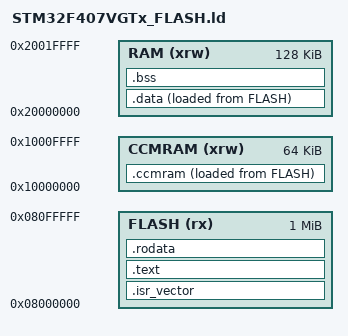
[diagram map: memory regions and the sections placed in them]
/**
 * @file     locate: linker/STM32F407VGTx_FLASH.ld
 * @author  Yigit Cakirdogan
 * @brief   Custom GNU LD Linker Script for STM32F407VGTx (1024KB Flash, 128KB SRAM, 64KB CCMRAM)
 */

ENTRY(Reset_Handler)

_estack = ORIGIN(RAM) + LENGTH(RAM);

_Min_Heap_Size  = 0x0000; /* Zero heap policy for deterministic bare-metal firmware */
_Min_Stack_Size = 0x1000; /* 4 KB Main Stack (MSP) */

MEMORY
{
  CCMRAM (xrw) : ORIGIN = 0x10000000, LENGTH = 64K
  RAM    (xrw) : ORIGIN = 0x20000000, LENGTH = 128K
  FLASH  (rx)  : ORIGIN = 0x08000000, LENGTH = 1024K
}

SECTIONS
{
  .isr_vector :
  {
    . = ALIGN(4);
    KEEP(*(.isr_vector))
    . = ALIGN(4);
  } >FLASH

  .text :
  {
    . = ALIGN(4);
    *(.text)
    *(.text*)
    *(.glue_7)
    *(.glue_7t)
    KEEP (*(.init))
    KEEP (*(.fini))
    . = ALIGN(4);
    _etext = .;
  } >FLASH

  .rodata :
  {
    . = ALIGN(4);
    *(.rodata)
    *(.rodata*)
    . = ALIGN(4);
  } >FLASH

  _sidata = LOADADDR(.data);

  .data :
  {
    . = ALIGN(4);
    _sdata = .;
    *(.data)
    *(.data*)
    . = ALIGN(4);
    _edata = .;
  } >RAM AT> FLASH

  _siccmram = LOADADDR(.ccmram);

  .ccmram :
  {
    . = ALIGN(4);
    _sccmram = .;
    *(.ccmram)
    *(.ccmram*)
    . = ALIGN(4);
    _eccmram = .;
  } >CCMRAM AT> FLASH

  .bss :
  {
    . = ALIGN(4);
    _sbss = .;
    __bss_start__ = _sbss;
    *(.bss)
    *(.bss*)
    *(COMMON)
    . = ALIGN(4);
    _ebss = .;
    __bss_end__ = _ebss;
  } >RAM
}
